# STM32H573 register map
File version: 1.8
CPU: CM33 r0p0, little endian, MPU, FPU, 4 interrupt priority bits
Registers are 32-bit, read-write, reset 0x0 unless marked. A register's access mark holds for its fields unless they carry their own. Offsets are from the block's base; [hi:lo] are bit positions; {n}, {i} and the like mark numbered series; 'fields as' and 'values as' point back to an identical list.

## AES — Advanced encryption standard hardware accelerator
Base 0x420C0000
Same registers: SEC_AES 0x520C0000
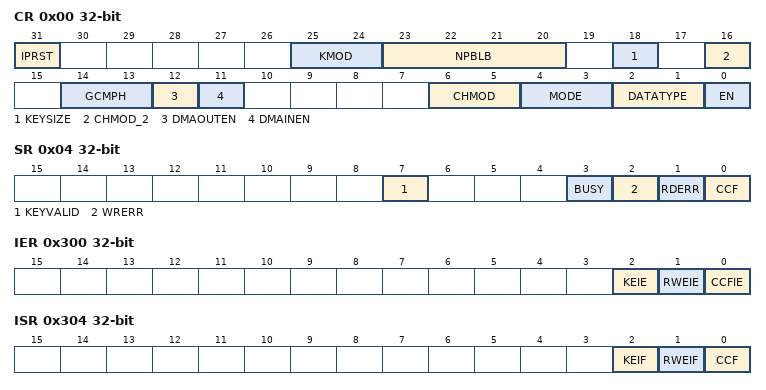
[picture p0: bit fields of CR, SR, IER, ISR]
0x00 CR — AES control register
  [31] IPRST — AES peripheral software reset Setting the bit resets the AES peripheral, putting all registers to their default values, except the IPRST bit itself. Hence, any key-relative data is lost. For this reason, it is recommended to set the bit before handing over the AES to a less secure application. The bit must be low while writing any configuration registers.
  [25:24] KMOD — Key mode selection The bitfield defines how the AES key can be used by the application: Others: Reserved With normal key selection, the key registers are freely usable, no specific usage or protection applies to AES_DIN and AES_DOUT registers. With selection of shared key from SAES co-processor, the AES peripheral automatically loads its key registers with the data stored in the key registers of the SAES peripheral. The key value is available in key registers when BUSY bit is cleared and KEYVALID is set in the AES_SR register. Key error flag KEIF is set otherwise in the AES_ISR register. The bitfield must be set only when KEYSIZE is correct, and when a shared key decryption sequence has been successfully completed in SAES co-processor. N/AAttempts to write the bitfield are ignored when the BUSY flag of AES_SR register is set, as well as when the EN bit of the AES_CR register is set before the write access and it is not cleared by that write access.
    0=Normal key mode. Key registers are freely usable; 2=Shared key mode. If shared key mode is properly initialized in SAES peripheral, the AES peripheral automatically loads its key registers with the data stored in the SAES key registers. The key value is available in AES key registers when BUSY bit is cleared and KEYVALID is set in the AES_SR register. Key error flag KEIF is set otherwise in the AES_ISR register
  [23:20] NPBLB — Number of padding bytes in last block The bitfield sets the number of padding bytes in last block of payload: ...
  [18] KEYSIZE — Key size selection This bitfield defines the length of the key used in the AES cryptographic core, in bits: Attempts to write the bit are ignored when the BUSY flag of AES_SR register is set, as well as when the EN bit of the AES_CR register is set before the write access and it is not cleared by that write access.
    0=AES128 (128); 1=AES256 (256)
  [16] CHMOD_2 — Chaining mode selection This bitfield selects the AES chaining mode: others: Reserved Attempts to write the bitfield are ignored when the BUSY flag of AES_SR register is set, as well as when the EN bit of the AES_CR register is set before the write access and it is not cleared by that write access.
    0=CHMOD (Mode as per CHMOD (ECB, CBC, CTR, GCM)); 1=CCM (Counter with CBC-MAC (CCM) - CHMOD must be 0 (ECB))
  [14:13] GCMPH — GCM or CCM phase selection This bitfield selects the phase of GCM, GMAC or CCM algorithm: The bitfield has no effect if other than GCM, GMAC or CCM algorithms are selected (through the ALGOMODE bitfield).
    0=Init phase; 1=Header phase; 2=Payload phase; 3=Final Phase
  [12] DMAOUTEN — DMA output enable This bit enables/disables data transferring with DMA, in the output phase: When the bit is set, DMA requests are automatically generated by AES during the output data phase. This feature is only effective when Mode 1 or Mode 3 is selected through the MODE[1:0] bitfield. It is not effective for Mode 2 (key derivation).
    0=Disable DMA Output; 1=Enabled DMA Output
  [11] DMAINEN — DMA input enable This bit enables/disables data transferring with DMA, in the input phase: When the bit is set, DMA requests are automatically generated by AES during the input data phase. This feature is only effective when Mode 1 or Mode 3 is selected through the MODE[1:0] bitfield. It is not effective for Mode 2 (key derivation).
    0=Disable DMA Input; 1=Enable DMA Input
  [6:5] CHMOD — Chaining mode selection This bitfield selects the AES chaining mode: others: Reserved Attempts to write the bitfield are ignored when the BUSY flag of AES_SR register is set, as well as when the EN bit of the AES_CR register is set before the write access and it is not cleared by that write access.
    0=ECB (Electronic codebook (ECB) / Counter with CBC-MAC (CCM) if CHMOD2 is 1); 1=CBC (Cipher-block chaining (CBC)); 2=CTR (Counter mode (CTR)); 3=GCM (Galois counter mode (GCM) and Galois message authentication code (GMAC))
  [4:3] MODE — AES operating mode This bitfield selects the AES operating mode: Attempts to write the bitfield are ignored when the BUSY flag of AES_SR register is set, as well as when the EN bit of the AES_CR register is set before the write access and it is not cleared by that write access.
    0=Mode 1: encryption; 1=Mode 2: key derivation (or key preparation for ECB/CBC decryption); 2=Mode 3: decryption; 3=Mode 4: key derivation then single decryption
  [2:1] DATATYPE — Data type selection This bitfield defines the format of data written in the AES_DINR register or read from the AES_DOUTR register, through selecting the mode of data swapping: For more details, refer to . Attempts to write the bitfield are ignored when the BUSY flag of AES_SR register is set, as well as when the EN bit of the AES_CR register is set before the write access and it is not cleared by that write access.
    0=None (Word); 1=Half-word (16-bit); 2=Byte (8-bit); 3=Bit
  [0] EN — AES enable This bit enables/disables the AES peripheral: At any moment, clearing then setting the bit re-initializes the AES peripheral. This bit is automatically cleared by hardware upon the completion of the key preparation (Mode 2) and upon the completion of GCM/GMAC/CCM initial phase. The bit cannot be set as long as KEYVALID = 0. Note: With KMOD[1:0] other than 00, use the IPRST bit rather than the bit EN.
    0=Disabled (Disable AES); 1=Enabled (Enable AES)
0x04 SR ro — AES status register
  [7] KEYVALID — Key Valid flag This bit is set by hardware when the amount of key information defined by KEYSIZE in AES_CR has been loaded in AES_KEYx key registers. In normal mode when KEYSEL equals to zero, the application must write the key registers in the correct sequence, otherwise the KEIF flag of the AES_ISR register is set and KEYVALID stays at zero. When KEYSEL is different from zero the BUSY flag is automatically set by AES. When key is loaded successfully, the BUSY flag is cleared and KEYVALID set. Upon an error, the KEIF flag of the AES_ISR register is set, the BUSY flag cleared and KEYVALID kept at zero. When the KEIF flag is set, the application must clear it through the AES_ICR register, otherwise KEYVALID cannot be set. See the KEIF bit description for more details. For more information on key loading please refer to .
  [3] BUSY — Busy This flag indicates whether AES is idle or busy during GCM payload encryption phase: When the flag indicates 'idle', the current GCM encryption processing may be suspended to process a higher-priority message. In other chaining modes, or in GCM phases other than payload encryption, the flag must be ignored for the suspend process. The flag is set when transferring a shared key from SAES peripheral.
    0=Idle; 1=Busy
  [2] WRERR — Write error This flag indicates the detection of an unexpected write operation to the AES_DINR register (during computation or data output phase): The flag is set by hardware. It is cleared by software upon setting the RWEIF bit of the AES_ICR register. Upon the flag setting, an interrupt is generated if enabled through the RWEIE bit of the AES_ICR register. The flag setting has no impact on the AES operation. Unexpected write is ignored.
    0=NoError (Write error not detected); 1=Error (Write error detected)
  [1] RDERR — Read error flag This flag indicates the detection of an unexpected read operation from the AES_DOUTR register (during computation or data input phase): The flag is set by hardware. It is cleared by software upon setting the RWEIF bit of the AES_ICR register. Upon the flag setting, an interrupt is generated if enabled through the RWEIE bit of the AES_ICR register. The flag setting has no impact on the AES operation. Unexpected read returns zero.
    0=NoError (Read error not detected); 1=Error (Read error detected)
  [0] CCF — Computation completed flag This bit mirrors the CCF bit of the AES_ISR register.
    0=Complete (Computation complete); 1=NotComplete (Computation not complete)
0x08 DINR wo — AES data input register
  [31:0] DIN — Input data word A four-fold sequential write to this bitfield during the input phase results in writing a complete 128-bit block of input data to the AES peripheral. From the first to the fourth write, the corresponding data weights are [127:96], [95:64], [63:32], and [31:0]. Upon each write, the data from the 32-bit input buffer are handled by the data swap block according to the DATATYPE[1:0] bitfield, then written into the AES core 128-bit input buffer. The data signification of the input data block depends on the AES operating mode: - Mode 1 (encryption): plaintext - Mode 2 (key derivation): the bitfield is not used (AES_KEYRx registers used for input) - Mode 3 (decryption): ciphertext The data swap operation is described in page 1149.
0x0C DOUTR ro — AES data output register
  [31:0] DOUT — Output data word This read-only bitfield fetches a 32-bit output buffer. A four-fold sequential read of this bitfield, upon the computation completion (CCF set), virtually reads a complete 128-bit block of output data from the AES peripheral. Before reaching the output buffer, the data produced by the AES core are handled by the data swap block according to the DATATYPE[1:0] bitfield. Data weights from the first to the fourth read operation are: [127:96], [95:64], [63:32], and [31:0]. The data signification of the output data block depends on the AES operating mode: - Mode 1 (encryption): ciphertext - Mode 2 (key derivation): the bitfield is not used - Mode 3 (decryption): plaintext The data swap operation is described in page 1149.
0x10 KEYR0 wo — AES key register 0
  [31:0] KEY — Cryptographic key, bits [31:0] This write-only bitfield contains the bits [31:0] of the AES encryption or decryption key, depending on the operating mode: - In Mode 1 (encryption), Mode 2 (key derivation): the value to write into the bitfield is the encryption key. - In Mode 3 (decryption): the value to write into the bitfield is the encryption key to be derived before being used for decryption. The AES_KEYRx registers may be written only when KEYSIZE value is correct and when the AES peripheral is disabled (EN bit of the AES_CR register cleared). A special writing sequence is also required, as described in KEYVALID bit of the AES_SR register. Note that, if KMOD[1:0] = 10 (shared key), the key is directly loaded from SAES peripheral to AES_KEYRx registers (hence writes to key register is ignored and KEIF is set). Refer to for more details.
{0x10+4i} KEYR{i} wo (i=1..3) — AES key register {i}
  [31:0] KEY — Cryptographic key, bits [{32i+31}:{32i}] Refer to the AES_KEYR0 register for description of the KEY[255:0] bitfield.
0x20 IVR0 — AES initialization vector register 0
  [31:0] IVI — Initialization vector input, bits [31:0] Refer to for description of the IVI[127:0] bitfield. The initialization vector is only used in chaining modes other than ECB. The AES_IVRx registers may be written only when the AES peripheral is disabled
{0x20+4i} IVR{i} (i=1..3) — AES initialization vector register {i}
  [31:0] IVI — Initialization vector input, bits [{32i+31}:{32i}] Refer to the AES_IVR0 register for description of the IVI[128:0] bitfield.
{0x20+4i} KEYR{i} wo (i=4..7) — AES key register {i}
  fields as KEYR1
{0x40+4i} SUSP{i}R (i=0..7) — AES suspend registers
  [31:0] SUSP — AES suspend Upon suspend operation, this bitfield of the corresponding AES_SUSPxR register takes the value of one of internal AES registers.
0x300 IER — AES interrupt enable register
  [all] fields
    0=Disabled (Interrupt is disabled (masked)); 1=Enabled (Interrupt is enabled (not masked))
  [2] KEIE — Key error interrupt enable This bit enables or disables (masks) the AES interrupt generation when KEIF (key error flag) is set.
  [1] RWEIE — Read or write error interrupt enable This bit enables or disables (masks) the AES interrupt generation when RWEIF (read and/or write error flag) is set.
  [0] CCFIE — Computation complete flag interrupt enable This bit enables or disables (masks) the AES interrupt generation when CCF (computation complete flag) is set.
0x304 ISR ro — AES interrupt status register
  [2] KEIF — Key error interrupt flag This read-only bit is set by hardware when key information failed to load into key registers. Setting the corresponding bit of the AES_ICR register clears the KEIF and generates interrupt if the KEIE bit of the AES_IER register is set. KEIF is triggered upon any of the following errors: AES_KEYRx register write does not respect the correct order. (For KEYSIZE = 0, AES_KEYR0 then AES_KEYR1 then AES_KEYR2 then AES_KEYR3 register, or reverse. For KEYSIZE = 1, AES_KEYR0 then AES_KEYR1 then AES_KEYR2 then AES_KEYR3 then AES_KEYR4 then AES_KEYR5 then AES_KEYR6 then AES_KEYR7, or reverse). KEIF must be cleared by the application software, otherwise KEYVALID cannot be set.
    0=No error detected; 1=Error (The error detected)
  [1] RWEIF — Read or write error interrupt flag This read-only bit is set by hardware when a RDERR or a WRERR error flag is set in the AES_SR register. RWEIF bit is cleared when application sets the corresponding bit of AES_ICR register. An interrupt is generated if the RWEIE bit has been previously set in the AES_IER register. This flags has no meaning when key derivation mode is selected.
    0=No error detected; 1=Error (The error detected)
  [0] CCF — Computation complete flag This flag indicates whether the computation is completed: The flag is set by hardware upon the completion of the computation. It is cleared by software, upon setting the CCF bit of the AES_ICR register. Upon the flag setting, an interrupt is generated if enabled through the CCFIE bit of the AES_IER register. The flag is significant only when the DMAOUTEN bit is 0. It may stay high when DMA_EN is 1.
    0=NotCompleted (Computation not completed); 1=Completed (Computation completed)
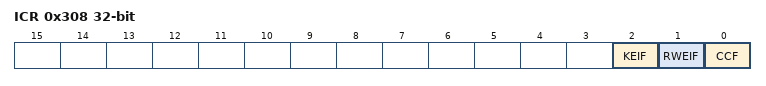
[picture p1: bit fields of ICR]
0x308 ICR wo — AES interrupt clear register
  [all] fields
    1=Clear (Setting this bit clears corresponding interrupt status bit)
  [2] KEIF — Key error interrupt flag clear Setting this bit clears the KEIF status bit of the AES_ISR register.
  [1] RWEIF — Read or write error interrupt flag clear Setting this bit clears the RWEIF status bit of the AES_ISR register, and both RDERR and WRERR flags in the AES_SR register.
  [0] CCF — Computation complete flag clear Setting this bit clears the CCF status bit of the AES_SR and AES_ISR registers.
